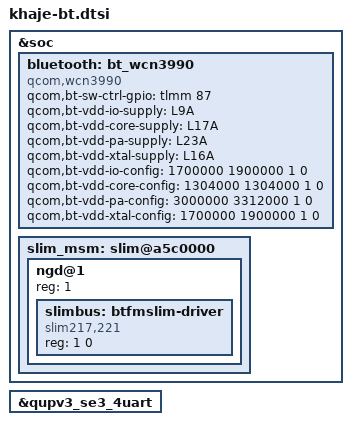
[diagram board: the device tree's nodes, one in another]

&soc {
	bluetooth: bt_wcn3990 {
                compatible = "qcom,wcn3990";
                qcom,bt-sw-ctrl-gpio = <&tlmm 87 0>; /* SW_CTRL */
                qcom,bt-vdd-io-supply =   <&L9A>;  /* IO */
                qcom,bt-vdd-core-supply = <&L17A>; /* RFA */
                qcom,bt-vdd-pa-supply =   <&L23A>; /* CH0 */
                qcom,bt-vdd-xtal-supply = <&L16A>; /* XO */

                qcom,bt-vdd-io-config = <1700000 1900000 1 0>;
                qcom,bt-vdd-core-config = <1304000 1304000 1 0>;
                qcom,bt-vdd-pa-config = <3000000 3312000 1 0>;
                qcom,bt-vdd-xtal-config = <1700000 1900000 1 0>;
	};
        slim_msm: slim@a5c0000 {
                status =  "ok";
                ngd@1 {
                    reg = <1>;
                    #address-cells = <1>;
                    #size-cells = <1>;
                    //slimbus child nodes
                    slimbus: btfmslim-driver {
                            compatible = "slim217,221";
                            reg = <1 0>;
                    };
                };
        };

};

&qupv3_se3_4uart {
   status = "ok";
};
